# R7FA4W1AD register map
Vendor: Renesas; Series: RA4; File version: 1.0
CPU: CM4 r0p1, little endian, MPU, FPU, VTOR, 4 interrupt priority bits
Registers are 8-bit, read-write, reset 0x0 unless marked. A register's access mark holds for its fields unless they carry their own. Offsets are from the block's base; [hi:lo] are bit positions; {n}, {i} and the like mark numbered series; 'fields as' and 'values as' point back to an identical list.

## PMISC — Miscellaneous Port Control Register
Base 0x40040D00
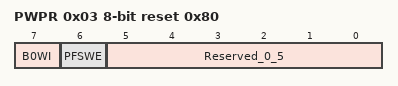
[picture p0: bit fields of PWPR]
0x03 PWPR reset 0x80 — Write,Protect Register
  [7] B0WI — PFSWE Bit Write Disable
  [6] PFSWE — PFS Register Write Enable
  [5:0] Reserved_0_5 — These bits are read as 000000. The write value should be 000000.

## ELC — Event Link Controller
Base 0x40041000
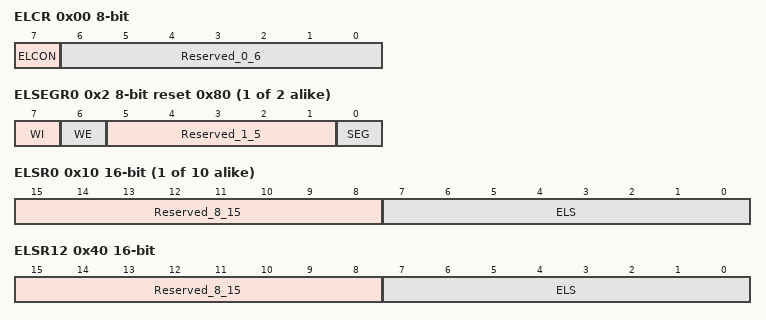
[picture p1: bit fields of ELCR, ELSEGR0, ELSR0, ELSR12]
0x00 ELCR — Event Link Controller Register
  [7] ELCON — All Event Link Enable
  [6:0] Reserved_0_6 — These bits are read as 0000000. The write value should be 0000000.
{0x2+2i} ELSEGR{i} (i=0..1) reset 0x80 — Event Link Software Event Generation Register {i}
  [7] WI wo — ELSEGR Register Write Disable
  [6] WE — SEG Bit Write Enable
  [5:1] Reserved_1_5 — These bits are read as 00000. The write value should be 00000.
  [0] SEG wo — Software Event Generation
{0x10+4i} ELSR{i} (i=0..9) 16-bit — Event Link Setting Register {i}
  [15:8] Reserved_8_15 — These bits are read as 00000000. The write value should be 00000000.
  [7:0] ELS — Event Link Select
0x40 ELSR12 16-bit — Event Link Setting Register 12
  fields as ELSR0
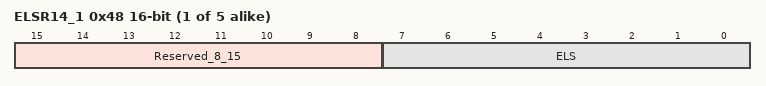
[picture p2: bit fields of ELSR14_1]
{0x10+4i} ELSR{i}_1 (i=14..18) 16-bit — Event Link Setting Register {i}
  fields as ELSR0

## DOC — Data Operation Circuit
Base 0x40054100
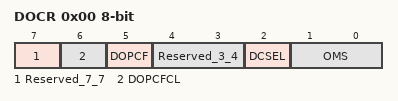
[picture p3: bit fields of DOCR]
0x00 DOCR — DOC Control Register
  [7] Reserved_7_7 — This bit is read as 0. The write value should be 0.
  [6] DOPCFCL — DOPCF Clear
  [5] DOPCF ro — Data Operation Circuit FlagIndicates the result of an operation.
  [4:3] Reserved_3_4 — These bits are read as 00. The write value should be 00.
  [2] DCSEL — Detection Condition Select
  [1:0] OMS — Operating Mode Select
0x02 DODIR 16-bit — DOC Data Input Register
  [15:0] DODIR — 16-bit read,write register in which 16-bit data for use in the operations are stored.
0x04 DODSR 16-bit — DOC Data Setting Register
  [15:0] DODSR — This register stores 16-bit data for use as a reference in data comparison mode. This register also stores the results of operations in data addition and data subtraction modes.

## CRC — CRC Calculator
Base 0x40074000
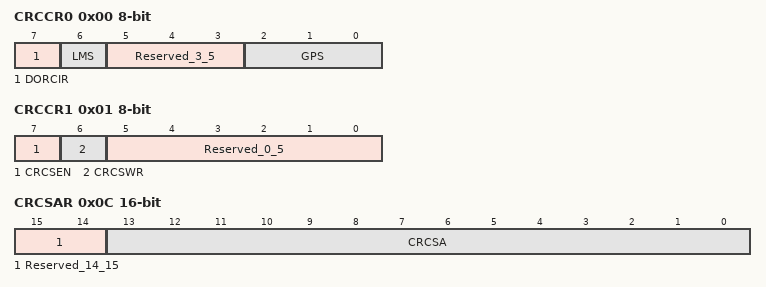
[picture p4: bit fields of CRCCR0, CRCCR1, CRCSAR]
0x00 CRCCR0 — CRC Control Register0
  [7] DORCIR wo — CRCDOR Register Clear
  [6] LMS — CRC Calculation Switching
  [5:3] Reserved_3_5 — These bits are read as 000. The write value should be 000.
  [2:0] GPS — CRC Generating Polynomial Switching
0x01 CRCCR1 — CRC Control Register1
  [7] CRCSEN — Snoop enable bit
  [6] CRCSWR — Snoop,on,write/read switch bit
  [5:0] Reserved_0_5 — These bits are read as 000000. The write value should be 000000.
0x04 CRCDIR 32-bit — CRC Data Input Register
  [31:0] CRCDIR — Calculation input Data (Case of CRC-32, CRC-32C )
0x04 CRCDIR_BY (alternate view of CRCDIR) — CRC Data Input Register (byte access)
  [7:0] CRCDIR_BY — Calculation input Data ( Case of CRC-8, CRC-16 or CRC,CCITT )
0x08 CRCDOR 32-bit — CRC Data Output Register
  [31:0] CRCDOR — Calculation output Data (Case of CRC-32, CRC-32C )
0x08 CRCDOR_HA 16-bit (alternate view of CRCDOR) — CRC Data Output Register (halfword access)
  [15:0] CRCDOR_HA — Calculation output Data (Case of CRC-16 or CRC,CCITT )
0x08 CRCDOR_BY (alternate view of CRCDOR) — CRC Data Output Register(byte access)
  [7:0] CRCDOR_BY — Calculation output Data (Case of CRC-8 )
0x0C CRCSAR 16-bit — Snoop Address Register
  [15:14] Reserved_14_15 — These bits are read as 00. The write value should be 00.
  [13:0] CRCSA — snoop address bitSet the I/O register address to snoop

## CAC — Clock Frequency Accuracy Measurement Circuit
Base 0x40044600
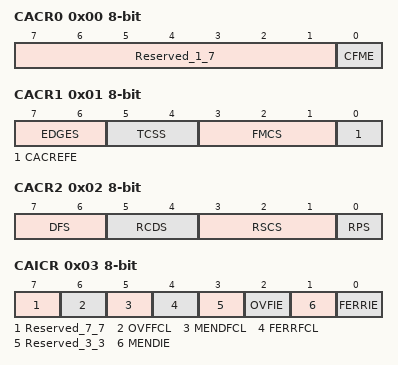
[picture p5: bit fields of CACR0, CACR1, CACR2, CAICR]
0x00 CACR0 — CAC Control Register 0
  [7:1] Reserved_1_7 — These bits are read as 0000000. The write value should be 0000000.
  [0] CFME — Clock Frequency Measurement Enable.
0x01 CACR1 — CAC Control Register 1
  [7:6] EDGES — Valid Edge Select
  [5:4] TCSS — Measurement Target Clock Frequency Division Ratio Select
  [3:1] FMCS — Measurement Target Clock Select
  [0] CACREFE — CACREF Pin Input Enable
0x02 CACR2 — CAC Control Register 2
  [7:6] DFS — Digital Filter Selection
  [5:4] RCDS — Measurement Reference Clock Frequency Division Ratio Select
  [3:1] RSCS — Measurement Reference Clock Select
  [0] RPS — Reference Signal Select
0x03 CAICR — CAC Interrupt Control Register
  [7] Reserved_7_7 — This bit is read as 0. The write value should be 0.
  [6] OVFFCL wo — OVFF Clear
  [5] MENDFCL wo — MENDF Clear
  [4] FERRFCL wo — FERRF Clear
  [3] Reserved_3_3 — This bit is read as 0. The write value should be 0.
  [2] OVFIE — Overflow Interrupt Request Enable
  [1] MENDIE — Measurement End Interrupt Request Enable
  [0] FERRIE — Frequency Error Interrupt Request Enable
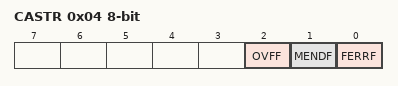
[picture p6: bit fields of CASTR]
0x04 CASTR ro — CAC Status Register
  [2] OVFF — Counter Overflow Flag
  [1] MENDF — Measurement End Flag
  [0] FERRF — Frequency Error Flag
0x06 CAULVR 16-bit — CAC Upper,Limit Value Setting Register
  [15:0] CAULVR — CAULVR is a 16-bit readable/writable register that stores the upper,limit value of the frequency.
0x08 CALLVR 16-bit — CAC Lower,Limit Value Setting Register
  [15:0] CALLVR — CALLVR is a 16-bit readable/writable register that stores the lower,limit value of the frequency.
0x0A CACNTBR 16-bit ro — CAC Counter Buffer Register
  [15:0] CACNTBR — CACNTBR is a 16-bit read,only register that retains the counter value at the time a valid reference signal edge is input
